# STM32L471xx register map
File version: 1.0
Registers are 32-bit, read-write, reset 0x0 unless marked. A register's access mark holds for its fields unless they carry their own. Offsets are from the block's base; [hi:lo] are bit positions; {n}, {i} and the like mark numbered series; 'fields as' and 'values as' point back to an identical list.

## EXTI — External Interrupt/Event Controller
Base 0x40010400
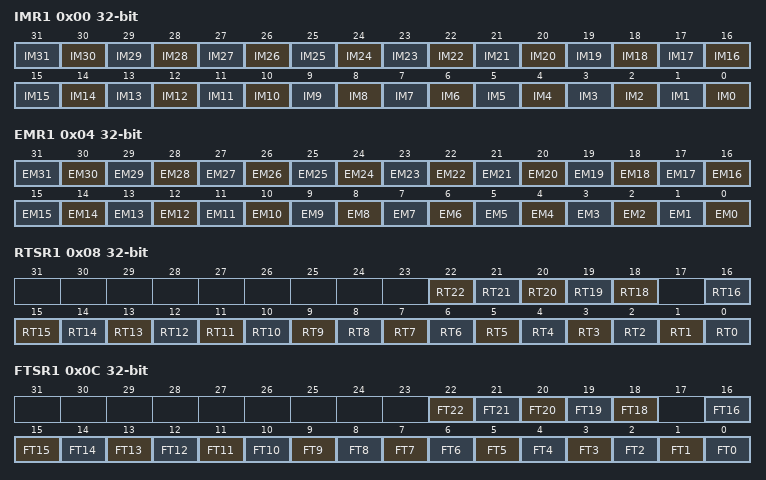
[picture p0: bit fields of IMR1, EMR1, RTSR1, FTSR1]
0x00 IMR1 — EXTI Interrupt mask register 1
  [n] IM{n} (n=0..31) — Interrupt Mask on line {n}
0x04 EMR1 — EXTI Event mask register 1
  [n] EM{n} (n=0..31) — Event Mask on line {n}
0x08 RTSR1 — EXTI Rising trigger selection register 1
  [n] RT{n} (n=18..22) — Rising trigger event configuration bit of line {n}
  [n] RT{n} (n=0..16) — Rising trigger event configuration bit of line {n}
0x0C FTSR1 — EXTI Falling trigger selection register 1
  [n] FT{n} (n=18..22) — Falling trigger event configuration bit of line {n}
  [n] FT{n} (n=0..16) — Falling trigger event configuration bit of line {n}
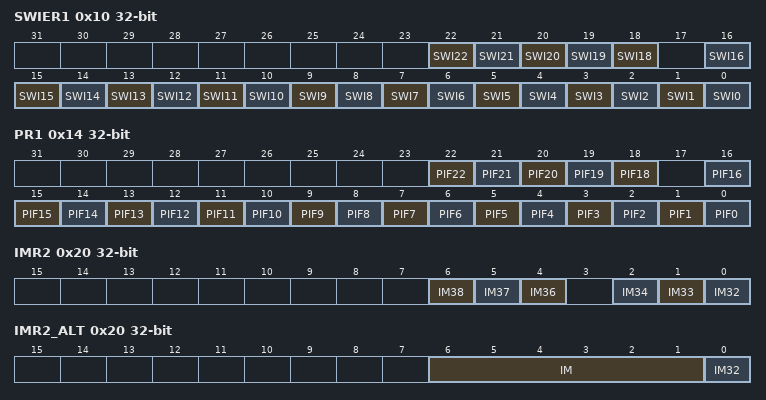
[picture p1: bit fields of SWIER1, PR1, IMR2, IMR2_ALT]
0x10 SWIER1 — EXTI Software interrupt event register 1
  [n] SWI{n} (n=18..22) — Software Interrupt on line {n}
  [n] SWI{n} (n=0..16) — Software Interrupt on line {n}
0x14 PR1 — EXTI Pending register 1
  [n] PIF{n} (n=18..22) — Pending bit for line {n}
  [n] PIF{n} (n=0..16) — Pending bit for line {n}
0x20 IMR2 — EXTI Interrupt mask register 2
  [6] IM38 — Interrupt Mask on line 38
  [5] IM37 — Interrupt Mask on line 37
  [4] IM36 — Interrupt Mask on line 36
  [2] IM34 — Interrupt Mask on line 34
  [1] IM33 — Interrupt Mask on line 33
  [0] IM32 — Interrupt Mask on line 32
0x20 IMR2_ALT (alternate view of IMR2) — EXTI Interrupt mask register 2
  [6:1] IM — Interrupt Mask all
  [0] IM32 — Interrupt Mask on line 32
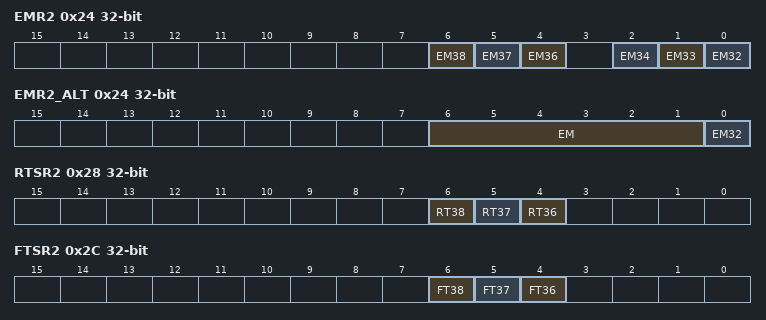
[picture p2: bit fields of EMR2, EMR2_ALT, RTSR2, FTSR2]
0x24 EMR2 — EXTI Event mask register 2
  [6] EM38 — Event Mask on line 38
  [5] EM37 — Event Mask on line 37
  [4] EM36 — Event Mask on line 36
  [2] EM34 — Event Mask on line 34
  [1] EM33 — Event Mask on line 33
  [0] EM32 — Event Mask on line 32
0x24 EMR2_ALT (alternate view of EMR2) — EXTI Event mask register 2
  [6:1] EM — Interrupt Mask all
  [0] EM32 — Event Mask on line 32
0x28 RTSR2 — EXTI Rising trigger selection register 2
  [6] RT38 — Rising trigger event configuration bit of line 38
  [5] RT37 — Rising trigger event configuration bit of line 37
  [4] RT36 — Rising trigger event configuration bit of line 36
0x2C FTSR2 — EXTI Falling trigger selection register 2
  [6] FT38 — Falling trigger event configuration bit of line 38
  [5] FT37 — Falling trigger event configuration bit of line 37
  [4] FT36 — Falling trigger event configuration bit of line 36
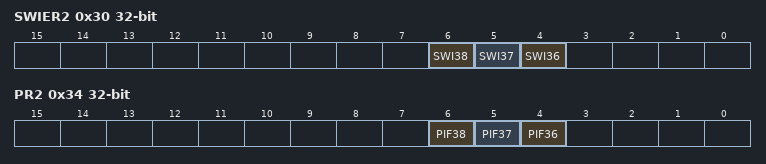
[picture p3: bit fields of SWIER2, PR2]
0x30 SWIER2 — EXTI Software interrupt event register 2
  [6] SWI38 — Software Interrupt on line 38
  [5] SWI37 — Software Interrupt on line 37
  [4] SWI36 — Software Interrupt on line 36
0x34 PR2 — EXTI Pending register 2
  [6] PIF38 — Pending bit for line 38
  [5] PIF37 — Pending bit for line 37
  [4] PIF36 — Pending bit for line 36

## FIREWALL
Base 0x40011C00
0x00 CSSA — Code Segment Start Address register
0x04 CSL — Code Segment Length register
0x08 NVDSSA — NON volatile data Segment Start Address register
0x0C NVDSL — NON volatile data Segment Length register
0x10 VDSSA — Volatile data Segment Start Address register
0x14 VDSL — Volatile data Segment Length register
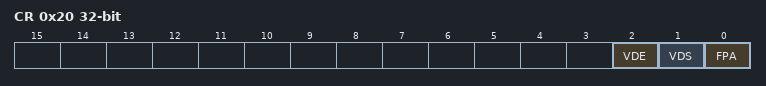
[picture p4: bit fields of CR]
0x20 CR — Configuration register
  [2] VDE — Volatile Data Execution
  [1] VDS — Volatile Data Sharing
  [0] FPA — Firewall Pre Arm

## SAI1 — Serial Audio Interface
Base 0x40015400
Same registers: SAI2 0x40015800
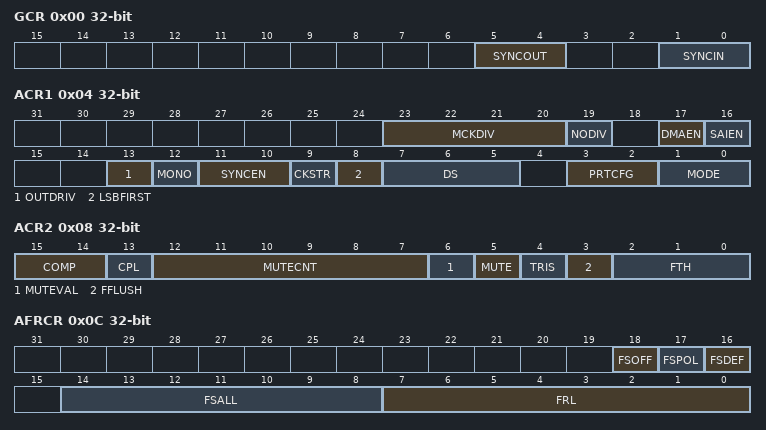
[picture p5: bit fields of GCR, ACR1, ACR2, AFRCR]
0x00 GCR — SAI global configuration register
  [5:4] SYNCOUT — SYNCOUT[1:0] bits (Synchronization Outputs)
  [1:0] SYNCIN — SYNCIN[1:0] bits (Synchronization Inputs)
0x04 ACR1 — SAI block x configuration register 1
  [23:20] MCKDIV — MCKDIV[3:0] (Master ClocK Divider)
  [19] NODIV — No Divider Configuration
  [17] DMAEN — DMA enable
  [16] SAIEN — Audio Block enable
  [13] OUTDRIV — Output Drive
  [12] MONO — Mono mode
  [11:10] SYNCEN — SYNCEN[1:0](SYNChronization ENable)
  [9] CKSTR — ClocK STRobing edge
  [8] LSBFIRST — LSB First Configuration
  [7:5] DS — DS[1:0] bits (Data Size)
  [3:2] PRTCFG — PRTCFG[1:0] bits (Protocol Configuration)
  [1:0] MODE — MODE[1:0] bits (Audio Block Mode)
0x08 ACR2 — SAI block x configuration register 2
  [15:14] COMP — COMP[1:0] (Companding mode)
  [13] CPL — CPL mode
  [12:7] MUTECNT — MUTECNT[5:0] (MUTE counter)
  [6] MUTEVAL — Muate value
  [5] MUTE — Mute mode
  [4] TRIS — TRIState Management on data line
  [3] FFLUSH — Fifo FLUSH
  [2:0] FTH — FTH[2:0](Fifo THreshold)
0x0C AFRCR — SAI block x frame configuration register
  [18] FSOFF — Frame Synchronization OFFset
  [17] FSPOL — Frame Synchronization POLarity
  [16] FSDEF — Frame Synchronization Definition
  [14:8] FSALL — FRL[6:0] (Frame synchronization active level length)
  [7:0] FRL — FRL[7:0](Frame length)
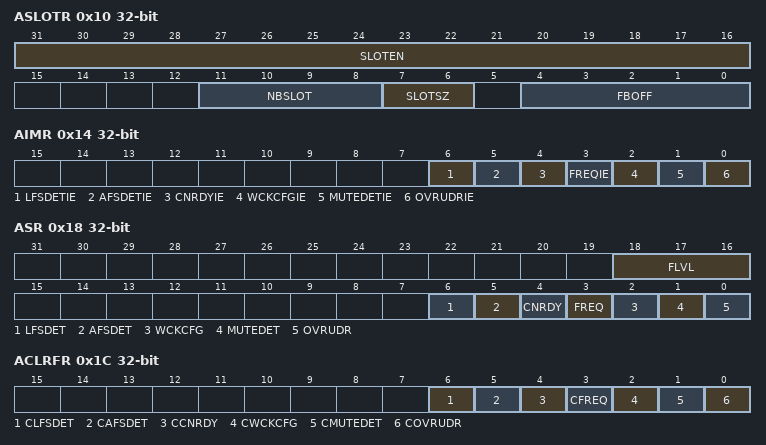
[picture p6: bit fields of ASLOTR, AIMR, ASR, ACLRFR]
0x10 ASLOTR — SAI block x slot register
  [31:16] SLOTEN — SLOTEN[15:0] (Slot Enable)
  [11:8] NBSLOT — NBSLOT[3:0] (Number of Slot in audio Frame)
  [7:6] SLOTSZ — SLOTSZ[1:0] (Slot size)
  [4:0] FBOFF — FRL[4:0](First Bit Offset)
0x14 AIMR — SAI block x interrupt mask register
  [6] LFSDETIE — Late frame synchronization detection interrupt enable
  [5] AFSDETIE — Anticipated frame synchronization detection interrupt enable
  [4] CNRDYIE — Codec not ready interrupt enable
  [3] FREQIE — FIFO request interrupt enable
  [2] WCKCFGIE — Wrong Clock Configuration interrupt enable
  [1] MUTEDETIE — Mute detection interrupt enable
  [0] OVRUDRIE — Overrun underrun interrupt enable
0x18 ASR — SAI block x status register
  [18:16] FLVL — FLVL[2:0] (FIFO Level Threshold)
  [6] LFSDET — Late frame synchronization detection
  [5] AFSDET — Anticipated frame synchronization detection
  [4] CNRDY — Codec not ready
  [3] FREQ — FIFO request
  [2] WCKCFG — Wrong Clock Configuration
  [1] MUTEDET — Mute detection
  [0] OVRUDR — Overrun underrun
0x1C ACLRFR — SAI block x clear flag register
  [6] CLFSDET — Clear Late frame synchronization detection
  [5] CAFSDET — Clear Anticipated frame synchronization detection
  [4] CCNRDY — Clear Codec not ready
  [3] CFREQ — Clear FIFO request
  [2] CWCKCFG — Clear Wrong Clock Configuration
  [1] CMUTEDET — Clear Mute detection
  [0] COVRUDR — Clear Overrun underrun
0x20 ADR — SAI block x data register
  [31:0] DATA
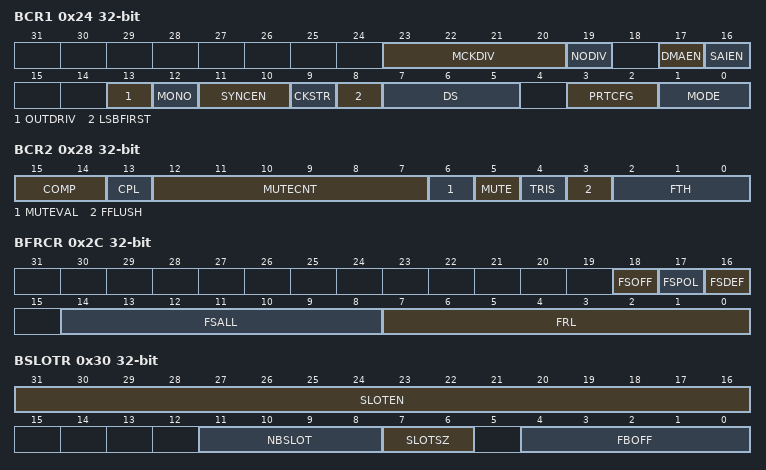
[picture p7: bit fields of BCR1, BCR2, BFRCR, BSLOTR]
0x24 BCR1 — SAI block x configuration register 1
  fields as ACR1
0x28 BCR2 — SAI block x configuration register 2
  fields as ACR2
0x2C BFRCR — SAI block x frame configuration register
  fields as AFRCR
0x30 BSLOTR — SAI block x slot register
  fields as ASLOTR
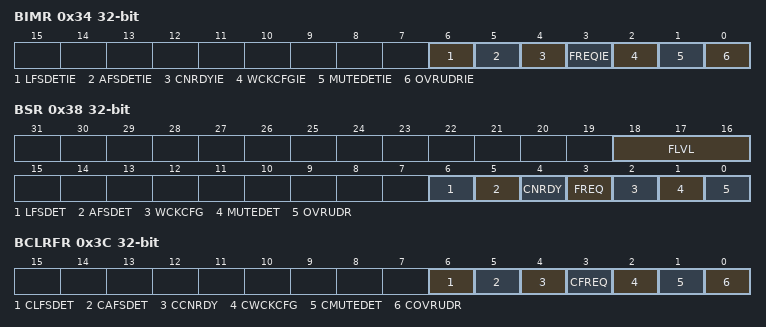
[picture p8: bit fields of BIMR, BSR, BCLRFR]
0x34 BIMR — SAI block x interrupt mask register
  fields as AIMR
0x38 BSR — SAI block x status register
  fields as ASR
0x3C BCLRFR — SAI block x clear flag register
  fields as ACLRFR
0x40 BDR — SAI block x data register
  [31:0] DATA
